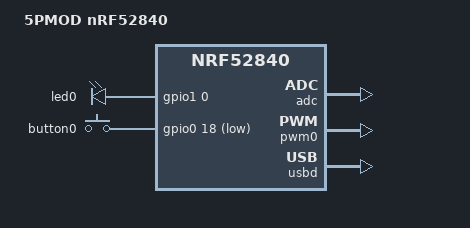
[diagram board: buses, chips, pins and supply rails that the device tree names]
/*
 * 5PMOD nRF52840 pinout
 *
 * Power connector GPIO: P0.29A*
 * Addressable RGB LED: P0.08
 * Discrete LED: P1.00
 *
 * Pin#  PMOD1    PMOD2    PMOD3    PMOD4    PMOD5
 *  1    P0.28A*  P0.30A*  P0.05A   P0.03A*  P0.02A*
 *  2    P1.08    P0.12    P0.19    P0.15    P0.24
 *  3    P0.11    P1.09    P0.21    P0.14    P0.20
 *  4    P0.25    P0.07    P0.23    P0.22    P0.17
 *  5    GND      GND      GND      GND      GND
 *  6    VCC      VCC      VCC      VCC      VCC
 *  7    P1.10*   P0.06    P0.16    P1.14*   P1.06*
 *  8    P1.15*   P0.26    P0.13    P1.02*   P1.04*
 *  9    P1.13*   P0.04A   P1.05*   P1.01*   P1.07*
 *  10   P1.11*   P0.31*   P0.27    P1.03*   P1.12*
 *  11   GND      GND      GND      GND      GND
 *  12   VCC      VCC      VCC      VCC      VCC
 *
 * PMODx-1: CS/CTS/_
 * PMODx-2: MOSI/TXD/_
 * PMODx-3: MISO/RXD/SCL
 * PMODx-4: SCK/RTS/SDA
 *
 * More details here:
 * https://reference.digilentinc.com/_media/reference/pmod/pmod-interface-specification-1_3_1.pdf
 */

/dts-v1/;
#include <nordic/nrf52840_qiaa.dtsi>
#include "5pmod_nrf52840-pinctrl.dtsi"

/*
 * All available device tree nodes can be found in
 * zephyr/dts/arm/nordic/nrf52840.dtsi
 */

/ {
	model = "5PMOD nRF52840";
	compatible = "nordic,5pmod-nrf52840";

	chosen {
		zephyr,sram = &sram0;
		zephyr,flash = &flash0;
	};

	leds {
		compatible = "gpio-leds";
		led0: led_0 {
			gpios = <&gpio1 0 0>;
		};
	};

	/* Set Kconfig option 'CONFIG_GPIO_AS_PINRESET=n' to use button as input */
	buttons {
		compatible = "gpio-keys";
		button0: button_0 {
			gpios = <&gpio0 18 (GPIO_PULL_UP | GPIO_ACTIVE_LOW)>;
		};
	};

	// TODO: Add WS2812 RGB LED

	// TODO: Add PMOD connector pinouts

	/* These aliases are provided for compatibility with samples */
	aliases {
		led0 = &led0;
		sw0 = &button0;
	};
};

&adc {
	status = "okay";
};

&gpiote {
	status = "okay";
};

&gpio0 {
	status = "okay";
};

&gpio1 {
	status = "okay";
};

&pwm0 {
	status = "okay";
	pinctrl-0 = <&pwm0_default>;
	pinctrl-1 = <&pwm0_sleep>;
	pinctrl-names = "default", "sleep";
};

zephyr_udc0: &usbd {
	status = "okay";
};
